# XMC4400 register map
Vendor: Infineon; File version: 1.5.3 (Reference Manual v1.5)
CPU: CM4 r2p0, little endian, MPU, FPU, 6 interrupt priority bits
Registers are 32-bit, read-write, reset 0x0 unless marked. A register's access mark holds for its fields unless they carry their own. Offsets are from the block's base; [hi:lo] are bit positions.

## POSIF0 — Position Interface 0
Base 0x40028000
Same registers: POSIF1 0x4002C000
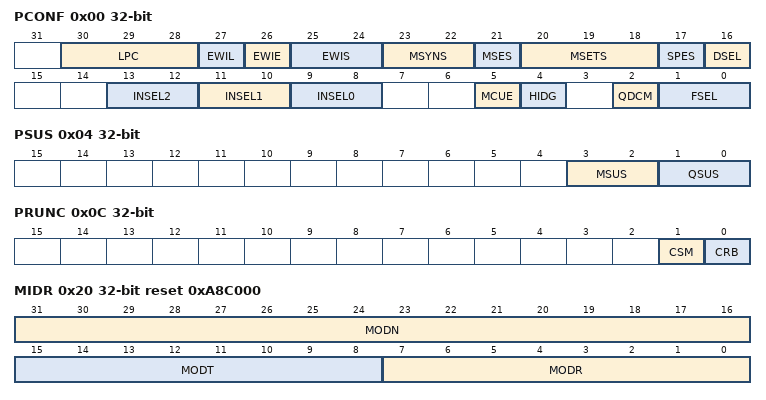
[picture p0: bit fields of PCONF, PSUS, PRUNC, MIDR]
0x00 PCONF — Service Request Processing configuration
  [30:28] LPC — Low Pass Filters Configuration
    0=Low pass filter disabled; 1=Low pass of 1 clock cycle; 2=Low pass of 2 clock cycles; 3=Low pass of 4 clock cycles; 4=Low pass of 8 clock cycles; 5=Low pass of 16 clock cycles; 6=Low pass of 32 clock cycles; 7=Low pass of 64 clock cycles
  [27] EWIL — External Wrong Hall Event active level
    0=POSIFx.EWHE[D...A] signal is active HIGH; 1=POSIFx.EWHE[D...A] signal is active LOW
  [26] EWIE — External Wrong Hall Event enable
    0=External wrong hall event emulation signal, POSIFx.EWHE[D...A], is disabled; 1=External wrong hall event emulation signal, POSIFx.EWHE[D...A], is enabled
  [25:24] EWIS — Wrong Hall Event selection
    0=POSIFx.EWHEA; 1=POSIFx.EWHEB; 2=POSIFx.EWHEC; 3=POSIFx.EWHED
  [23:22] MSYNS — PWM synchronization signal selector
    0=POSIFx.MSYNCA; 1=POSIFx.MSYNCB; 2=POSIFx.MSYNCC; 3=POSIFx.MSYNCD
  [21] MSES — Multi-Channel pattern update trigger edge
    0=The signal used to enable a pattern update is active on the rising edge; 1=The signal used to enable a pattern update is active on the falling edge
  [20:18] MSETS — Pattern update signal select
    0=POSIFx.MSETA; 1=POSIFx.MSETB; 2=POSIFx.MSETC; 3=POSIFx.MSETD; 4=POSIFx.MSETE; 5=POSIFx.MSETF; 6=POSIFx.MSETG; 7=POSIFx.MSETH
  [17] SPES — Edge selector for the sampling trigger
    0=Rising edge; 1=Falling edge
  [16] DSEL — Delay Pin selector
    0=POSIFx.HSDA; 1=POSIFx.HSDB
  [13:12] INSEL2 — Index/Hall input 3 selector
    0=POSIFx.IN2A; 1=POSIFx.IN2B; 2=POSIFx.IN2C; 3=POSIFx.IN2D
  [11:10] INSEL1 — PhaseB/Hall input 2 selector
    0=POSIFx.IN1A; 1=POSIFx.IN1B; 2=POSIFx.IN1C; 3=POSIFx.IN1D
  [9:8] INSEL0 — PhaseA/Hal input 1 selector
    0=POSIFx.IN0A; 1=POSIFx.IN0B; 2=POSIFx.IN0C; 3=POSIFx.IN0D
  [5] MCUE — Multi-Channel Pattern SW update enable
    0=Multi-Channel pattern update is controlled via HW; 1=Multi-Channel pattern update is controlled via SW
  [4] HIDG — Idle generation enable
  [2] QDCM — Position Decoder Mode selection
    0=Position encoder is in Quadrature Mode; 1=Position encoder is in Direction Count Mode
  [1:0] FSEL — Function Selector
    0=Hall Sensor Mode enabled; 1=Quadrature Decoder Mode enabled; 2=stand-alone Multi-Channel Mode enabled; 3=Quadrature Decoder and stand-alone Multi-Channel Mode enabled
0x04 PSUS — Service Request Processing Suspend Config
  [3:2] MSUS — Multi-Channel Mode Suspend Config
    0=Suspend request ignored; 1=Stop immediately. Multi-Channel pattern is not set to the reset value.; 2=Stop immediately. Multi-Channel pattern is set to the reset value.; 3=Suspend with the synchronization of the PWM signal. Multi-Channel pattern is set to the reset value at the same time of the synchronization.
  [1:0] QSUS — Quadrature Mode Suspend Config
    0=Suspend request ignored; 1=Stop immediately; 2=Suspend in the next index occurrence; 3=Suspend in the next phase (PhaseA or PhaseB) occurrence
0x08 PRUNS wo — Service Request Processing Run Bit Set
  [0] SRB — Set Run bit
0x0C PRUNC wo — Service Request Processing Run Bit Clear
  [1] CSM — Clear Current internal status
  [0] CRB — Clear Run bit
0x10 PRUN ro — Service Request Processing Run Bit Status
  [0] RB — Run Bit
    0=IDLE; 1=Running
0x20 MIDR ro reset 0xA8C000 (reset mask 0xFFFFFF00) — Module Identification register
  [31:16] MODN — Module Number
  [15:8] MODT — Module Type
  [7:0] MODR — Module Revision
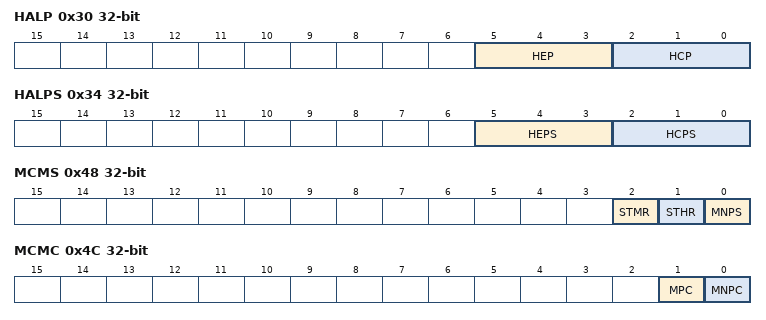
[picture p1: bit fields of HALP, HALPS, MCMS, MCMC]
0x30 HALP ro — Hall Sensor Patterns
  [5:3] HEP — Hall Expected Pattern
  [2:0] HCP — Hall Current Pattern
0x34 HALPS — Hall Sensor Shadow Patterns
  [5:3] HEPS — Shadow Hall expected Pattern
  [2:0] HCPS — Shadow Hall Current Pattern
0x40 MCM ro — Multi-Channel Pattern
  [15:0] MCMP
0x44 MCSM — Multi-Channel Shadow Pattern
  [15:0] MCMPS — Shadow Multi-Channel Pattern
0x48 MCMS wo — Multi-Channel Pattern Control set
  [2] STMR — Multi-Channel Shadow Transfer Request
  [1] STHR — Hall Pattern Shadow Transfer Request
  [0] MNPS — Multi-Channel Pattern Update Enable Set
0x4C MCMC wo — Multi-Channel Pattern Control clear
  [1] MPC — Multi-Channel Pattern clear
  [0] MNPC — Multi-Channel Pattern Update Enable Clear
0x50 MCMF ro — Multi-Channel Pattern Control flag
  [0] MSS — Multi-Channel Pattern update status
    0=Update of the Multi-Channel pattern is set; 1=Update of the Multi-Channel pattern is not set
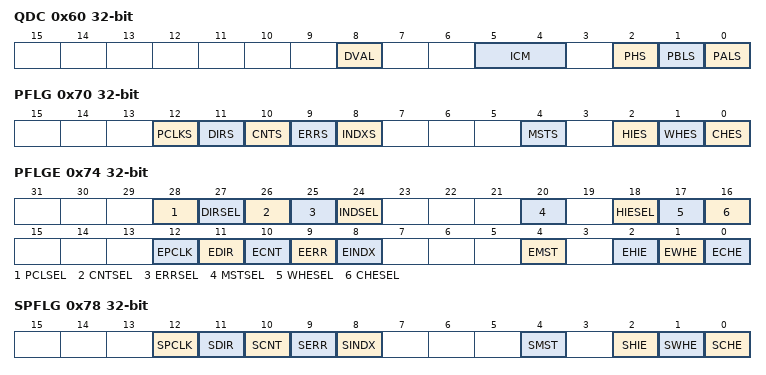
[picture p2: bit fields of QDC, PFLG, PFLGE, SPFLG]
0x60 QDC access per field — Quadrature Decoder Control
  [8] DVAL ro — Current rotation direction
    0=Counterclockwise rotation; 1=Clockwise rotation
  [5:4] ICM rw — Index Marker generations control
    0=No index marker generation on POSIFx.OUT3; 1=Only first index occurrence generated on POSIFx.OUT3; 2=All index occurrences generated on POSIFx.OUT3
  [2] PHS rw — Phase signals swap
    0=Phase A is the leading signal for clockwise rotation; 1=Phase B is the leading signal for clockwise rotation
  [1] PBLS rw — Phase B Level selector
    0=Phase B is active HIGH; 1=Phase B is active LOW
  [0] PALS rw — Phase A Level selector
    0=Phase A is active HIGH; 1=Phase A is active LOW
0x70 PFLG ro — Service Request Processing Interrupt Flags
  [12] PCLKS — Quadrature Period Clk Status
    0=Period clock not generated; 1=Period clock generated
  [11] DIRS — Quadrature Direction Change
    0=Change on direction not detected; 1=Change on direction detected
  [10] CNTS — Quadrature CLK Status
    0=Quadrature clock not generated; 1=Quadrature clock generated
  [9] ERRS — Quadrature Phase Error Status
    0=Phase Error event not detected; 1=Phase Error event detected
  [8] INDXS — Quadrature Index Status
    0=Index event not detected; 1=Index event detected
  [4] MSTS — Multi-Channel pattern shadow transfer status
    0=Shadow transfer not done; 1=Shadow transfer done
  [2] HIES — Hall Inputs Update Status
    0=Transition on the Hall Inputs not detected; 1=Transition on the Hall Inputs detected
  [1] WHES — Wrong Hall Event Status
    0=Wrong Hall Event not detected; 1=Wrong Hall Event detected
  [0] CHES — Correct Hall Event Status
    0=Correct Hall Event not detected; 1=Correct Hall Event detected
0x74 PFLGE — Service Request Processing Interrupt Enable
  [28] PCLSEL — Quadrature Period clock Event Service Request Selector
    0=Quadrature Period clock Event interrupt forward to POSIFx.SR0; 1=Quadrature Period clock Event interrupt forward to POSIFx.SR1
  [27] DIRSEL — Quadrature Direction Update Event Service Request Selector
    0=Quadrature Direction Update Event interrupt forward to POSIFx.SR0; 1=Quadrature Direction Update Event interrupt forward to POSIFx.SR1
  [26] CNTSEL — Quadrature Clock Event Service Request Selector
    0=Quadrature Clock Event interrupt forward to POSIFx.SR0; 1=Quadrature Clock Event interrupt forward to POSIFx.SR1
  [25] ERRSEL — Quadrature Phase Error Event Service Request Selector
    0=Quadrature Phase error Event interrupt forward to POSIFx.SR0; 1=Quadrature Phase error Event interrupt forward to POSIFx.SR1
  [24] INDSEL — Quadrature Index Event Service Request Selector
    0=Quadrature Index Event interrupt forward to POSIFx.SR0; 1=Quadrature Index Event interrupt forward to POSIFx.SR1
  [20] MSTSEL — Multi-Channel pattern Update Event Service Request Selector
    0=Multi-Channel pattern Update Event interrupt forward to POSIFx.SR0; 1=Multi-Channel pattern Update Event interrupt forward to POSIFx.SR1
  [18] HIESEL — Hall Inputs Update Event Service Request Selector
    0=Hall Inputs Update Event interrupt forward to POSIFx.SR0; 1=Hall Inputs Update Event interrupt forward to POSIFx.SR1
  [17] WHESEL — Wrong Hall Event Service Request Selector
    0=Wrong Hall Event interrupt forward to POSIFx.SR0; 1=Wrong Hall Event interrupt forward to POSIFx.SR1
  [16] CHESEL — Correct Hall Event Service Request Selector
    0=Correct Hall Event interrupt forward to POSIFx.SR0; 1=Correct Hall Event interrupt forward to POSIFx.SR1
  [12] EPCLK — Quadrature Period CLK interrupt Enable
    0=Quadrature Period CLK event interrupt disabled; 1=Quadrature Period CLK event interrupt enabled
  [11] EDIR — Quadrature direction change interrupt Enable
    0=Direction change event interrupt disabled; 1=Direction change event interrupt enabled
  [10] ECNT — Quadrature CLK interrupt Enable
    0=Quadrature CLK event interrupt disabled; 1=Quadrature CLK event interrupt enabled
  [9] EERR — Quadrature Phase Error Enable
    0=Phase error event interrupt disabled; 1=Phase error event interrupt enabled
  [8] EINDX — Quadrature Index Event Enable
    0=Index event interrupt disabled; 1=Index event interrupt enabled
  [4] EMST — Multi-Channel pattern shadow transfer enable
    0=Shadow transfer event interrupt disabled; 1=Shadow transfer event interrupt enabled
  [2] EHIE — Hall Input Update Enable
    0=Update of the Hall Inputs interrupt is disabled; 1=Update of the Hall Inputs interrupt is enabled
  [1] EWHE — Wrong Hall Event Enable
    0=Wrong Hall Event interrupt disabled; 1=Wrong Hall Event interrupt enabled
  [0] ECHE — Correct Hall Event Enable
    0=Correct Hall Event interrupt disabled; 1=Correct Hall Event interrupt enabled
0x78 SPFLG wo — Service Request Processing Interrupt Set
  [12] SPCLK — Quadrature period clock flag set
  [11] SDIR — Quadrature Direction flag set
  [10] SCNT — Quadrature CLK flag set
  [9] SERR — Quadrature Phase Error flag set
  [8] SINDX — Quadrature Index flag set
  [4] SMST — Multi-Channel Pattern shadow transfer flag set
  [2] SHIE — Hall Inputs Update Event flag set
  [1] SWHE — Wrong Hall Event flag set
  [0] SCHE — Correct Hall Event flag set
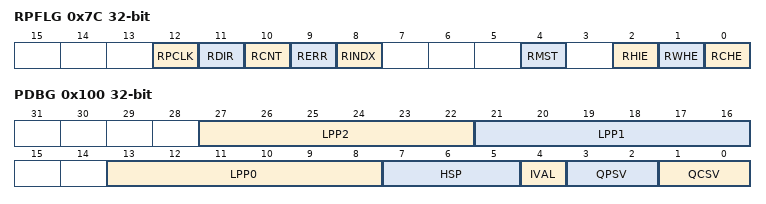
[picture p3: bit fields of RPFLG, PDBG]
0x7C RPFLG wo — Service Request Processing Interrupt Clear
  [12] RPCLK — Quadrature period clock flag clear
  [11] RDIR — Quadrature Direction flag clear
  [10] RCNT — Quadrature CLK flag clear
  [9] RERR — Quadrature Phase Error flag clear
  [8] RINDX — Quadrature Index flag clear
  [4] RMST — Multi-Channel Pattern shadow transfer flag clear
  [2] RHIE — Hall Inputs Update Event flag clear
  [1] RWHE — Wrong Hall Event flag clear
  [0] RCHE — Correct Hall Event flag clear
0x100 PDBG ro — POSIF Debug register
  [27:22] LPP2 — Actual count of the Low Pass Filter for POSI2
  [21:16] LPP1 — Actual count of the Low Pass Filter for POSI1
  [13:8] LPP0 — Actual count of the Low Pass Filter for POSI0
  [7:5] HSP — Hall Current Sampled Pattern
  [4] IVAL — Current Index Value
  [3:2] QPSV — Quadrature Decoder Previous state
  [1:0] QCSV — Quadrature Decoder Current state
